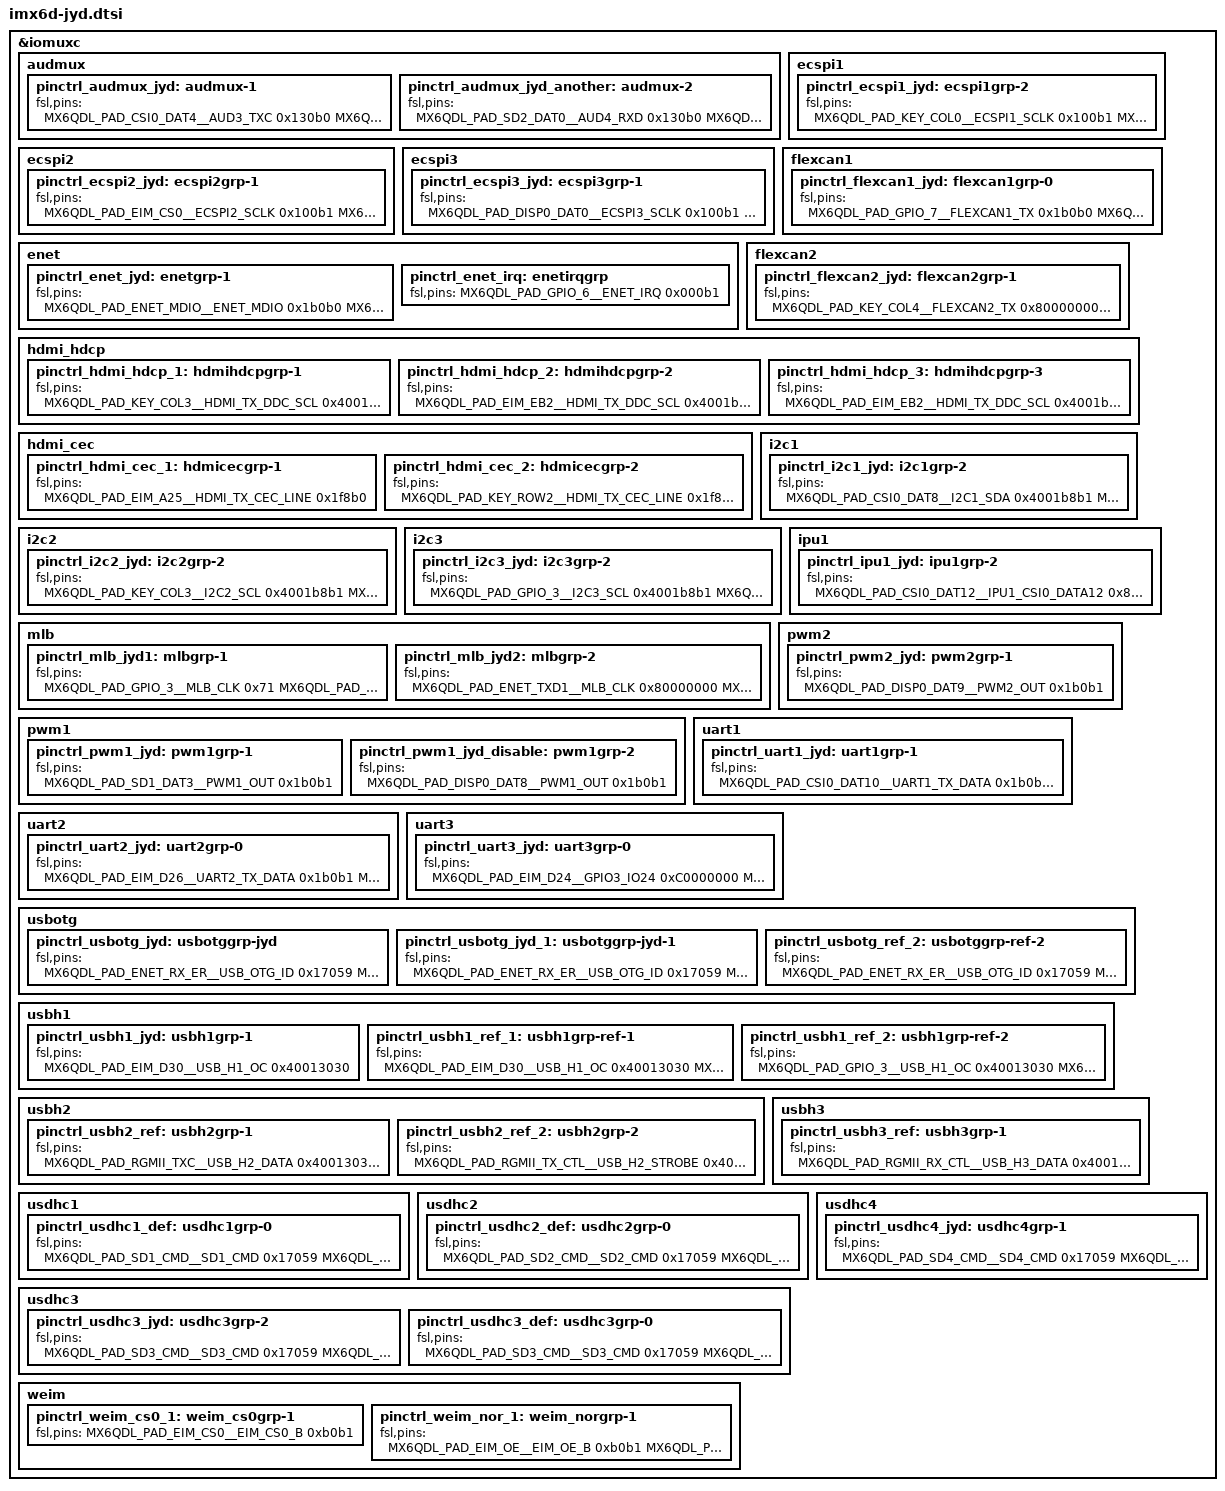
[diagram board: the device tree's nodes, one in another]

/*
 * Copyright 2013-2014 Freescale Semiconductor, Inc.
 *
 * This program is free software; you can redistribute it and/or modify
 * it under the terms of the GNU General Public License version 2 as
 * published by the Free Software Foundation.
 *
 */

#include "imx6d.dtsi"

&iomuxc {
	/* AUDMUX_PAD (AUD3/AUD4/AUD5/AUD6)*/
	audmux {
		/* EPT AUD3 (SGTL5000-Codec) */
		pinctrl_audmux_jyd: audmux-1 {
			fsl,pins = <
				MX6QDL_PAD_CSI0_DAT4__AUD3_TXC  0x130b0
				MX6QDL_PAD_CSI0_DAT5__AUD3_TXD  0x110b0
				MX6QDL_PAD_CSI0_DAT6__AUD3_TXFS 0x130b0
				MX6QDL_PAD_CSI0_DAT7__AUD3_RXD  0x130b0
			>;
		};
		/* AUD2 (Reserved) */
		pinctrl_audmux_jyd_another: audmux-2 {
			fsl,pins = <
				MX6QDL_PAD_SD2_DAT0__AUD4_RXD  0x130b0
				MX6QDL_PAD_SD2_DAT1__AUD4_TXFS 0x130b0
				MX6QDL_PAD_SD2_DAT2__AUD4_TXD  0x110b0
				MX6QDL_PAD_SD2_DAT3__AUD4_TXC  0x130b0
			>;
		};
	};

	ecspi1 {
		pinctrl_ecspi1_jyd: ecspi1grp-2 {
			fsl,pins = <
				MX6QDL_PAD_KEY_COL0__ECSPI1_SCLK 0x100b1
				MX6QDL_PAD_KEY_COL1__ECSPI1_MISO 0x100b1
				MX6QDL_PAD_KEY_ROW0__ECSPI1_MOSI 0x100b1
				MX6QDL_PAD_KEY_ROW1__ECSPI1_SS0 0x100b1
			>;
		};
	};

	ecspi2 {
		pinctrl_ecspi2_jyd: ecspi2grp-1 {
			fsl,pins = <
				MX6QDL_PAD_EIM_CS0__ECSPI2_SCLK 0x100b1
				MX6QDL_PAD_EIM_CS1__ECSPI2_MOSI 0x100b1
				MX6QDL_PAD_EIM_OE__ECSPI2_MISO 0x100b1
				MX6QDL_PAD_EIM_RW__ECSPI2_SS0 0x100b1
			>;
		};
	};
	
	ecspi3 {
		pinctrl_ecspi3_jyd: ecspi3grp-1 {
			fsl,pins = <
				MX6QDL_PAD_DISP0_DAT0__ECSPI3_SCLK 0x100b1
				MX6QDL_PAD_DISP0_DAT1__ECSPI3_MOSI 0x100b1
				MX6QDL_PAD_DISP0_DAT2__ECSPI3_MISO 0x100b1
				MX6QDL_PAD_DISP0_DAT3__ECSPI3_SS0 0x100b1
			>;
		};
	};

	enet {
		pinctrl_enet_jyd: enetgrp-1 {
			fsl,pins = <
				MX6QDL_PAD_ENET_MDIO__ENET_MDIO       0x1b0b0
				MX6QDL_PAD_ENET_MDC__ENET_MDC         0x1b0b0
				MX6QDL_PAD_RGMII_TXC__RGMII_TXC       0x1b0b0
				MX6QDL_PAD_RGMII_TD0__RGMII_TD0       0x1b0b0
				MX6QDL_PAD_RGMII_TD1__RGMII_TD1       0x1b0b0
				MX6QDL_PAD_RGMII_TD2__RGMII_TD2       0x1b0b0
				MX6QDL_PAD_RGMII_TD3__RGMII_TD3       0x1b0b0
				MX6QDL_PAD_RGMII_TX_CTL__RGMII_TX_CTL 0x1b0b0
				MX6QDL_PAD_ENET_REF_CLK__ENET_TX_CLK  0x1b0b0
				MX6QDL_PAD_RGMII_RXC__RGMII_RXC       0x1b0b0
				MX6QDL_PAD_RGMII_RD0__RGMII_RD0       0x1b0b0
				MX6QDL_PAD_RGMII_RD1__RGMII_RD1       0x1b0b0
				MX6QDL_PAD_RGMII_RD2__RGMII_RD2       0x1b0b0
				MX6QDL_PAD_RGMII_RD3__RGMII_RD3       0x1b0b0
				MX6QDL_PAD_RGMII_RX_CTL__RGMII_RX_CTL 0x1b0b0
				MX6QDL_PAD_GPIO_16__ENET_REF_CLK      0x4001b0a8
			>;
		};

		pinctrl_enet_irq: enetirqgrp {
			fsl,pins = <
				MX6QDL_PAD_GPIO_6__ENET_IRQ	      0x000b1
			>;
		};
	};
/*
	esai {
		pinctrl_esai_1: esaigrp-1 {
			fsl,pins = <
				MX6QDL_PAD_ENET_RXD0__ESAI_TX_HF_CLK 0x1b030
				MX6QDL_PAD_ENET_CRS_DV__ESAI_TX_CLK  0x1b030
				MX6QDL_PAD_ENET_RXD1__ESAI_TX_FS     0x1b030
				MX6QDL_PAD_ENET_TX_EN__ESAI_TX3_RX2  0x1b030
				MX6QDL_PAD_ENET_TXD1__ESAI_TX2_RX3   0x1b030
				MX6QDL_PAD_ENET_TXD0__ESAI_TX4_RX1   0x1b030
				MX6QDL_PAD_ENET_MDC__ESAI_TX5_RX0    0x1b030
				MX6QDL_PAD_NANDF_CS2__ESAI_TX0       0x1b030
				MX6QDL_PAD_NANDF_CS3__ESAI_TX1       0x1b030
			>;
		};

		pinctrl_esai_2: esaigrp-2 {
			fsl,pins = <
				MX6QDL_PAD_ENET_CRS_DV__ESAI_TX_CLK 0x1b030
				MX6QDL_PAD_ENET_RXD1__ESAI_TX_FS    0x1b030
				MX6QDL_PAD_ENET_TX_EN__ESAI_TX3_RX2 0x1b030
				MX6QDL_PAD_GPIO_5__ESAI_TX2_RX3     0x1b030
				MX6QDL_PAD_ENET_TXD0__ESAI_TX4_RX1  0x1b030
				MX6QDL_PAD_ENET_MDC__ESAI_TX5_RX0   0x1b030
				MX6QDL_PAD_GPIO_17__ESAI_TX0        0x1b030
				MX6QDL_PAD_NANDF_CS3__ESAI_TX1      0x1b030
				MX6QDL_PAD_ENET_MDIO__ESAI_RX_CLK   0x1b030
				MX6QDL_PAD_GPIO_9__ESAI_RX_FS       0x1b030
			>;
		};
	};
*/
	flexcan1 {
		/* EPT CAN1 */
		pinctrl_flexcan1_jyd: flexcan1grp-0 {
			fsl,pins = <
				MX6QDL_PAD_GPIO_7__FLEXCAN1_TX   0x1b0b0
				MX6QDL_PAD_GPIO_8__FLEXCAN1_RX  0x1b0b0
				MX6QDL_PAD_GPIO_19__GPIO4_IO05 0x1b0b0
			>;
		};
	};

	flexcan2 {
		/* EPT CAN2 */
		pinctrl_flexcan2_jyd: flexcan2grp-1 {
			fsl,pins = <
				MX6QDL_PAD_KEY_COL4__FLEXCAN2_TX 0x80000000
				MX6QDL_PAD_KEY_ROW4__FLEXCAN2_RX 0x80000000
			>;
		};
	};

	hdmi_hdcp {
		pinctrl_hdmi_hdcp_1: hdmihdcpgrp-1 {
			fsl,pins = <
				MX6QDL_PAD_KEY_COL3__HDMI_TX_DDC_SCL 0x4001b8b1
				MX6QDL_PAD_KEY_ROW3__HDMI_TX_DDC_SDA 0x4001b8b1
			>;
		};

		pinctrl_hdmi_hdcp_2: hdmihdcpgrp-2 {
			fsl,pins = <
				MX6QDL_PAD_EIM_EB2__HDMI_TX_DDC_SCL 0x4001b8b1
				MX6QDL_PAD_EIM_D16__HDMI_TX_DDC_SDA 0x4001b8b1
			>;
		};

		pinctrl_hdmi_hdcp_3: hdmihdcpgrp-3 {
			fsl,pins = <
				MX6QDL_PAD_EIM_EB2__HDMI_TX_DDC_SCL  0x4001b8b1
				MX6QDL_PAD_KEY_ROW3__HDMI_TX_DDC_SDA 0x4001b8b1
			>;
		};
	};

	hdmi_cec {
		pinctrl_hdmi_cec_1: hdmicecgrp-1 {
			fsl,pins = <
				MX6QDL_PAD_EIM_A25__HDMI_TX_CEC_LINE 0x1f8b0
			>;
		};

		pinctrl_hdmi_cec_2: hdmicecgrp-2 {
			fsl,pins = <
				MX6QDL_PAD_KEY_ROW2__HDMI_TX_CEC_LINE 0x1f8b0
			>;
		};
	};
	
	i2c1 {
		/* EPT I2C1 (MMA8451Q / SGTL5000 / ADV7280) */
		pinctrl_i2c1_jyd: i2c1grp-2 {
			fsl,pins = <
				MX6QDL_PAD_CSI0_DAT8__I2C1_SDA 0x4001b8b1
				MX6QDL_PAD_CSI0_DAT9__I2C1_SCL 0x4001b8b1
			>;
		};
	};

	i2c2 {
		/* EPT I2C2 (PMIC / LVDS / HDMI / TOUCH) */
		pinctrl_i2c2_jyd: i2c2grp-2 {
			fsl,pins = <
				MX6QDL_PAD_KEY_COL3__I2C2_SCL 0x4001b8b1
				MX6QDL_PAD_KEY_ROW3__I2C2_SDA 0x4001b8b1
			>;
		};
	};

	i2c3 {
		/* EPT I2C3 (ISL29032 / MAG3110 / FM-SI4754) */
		pinctrl_i2c3_jyd: i2c3grp-2 {
			fsl,pins = <
				MX6QDL_PAD_GPIO_3__I2C3_SCL 0x4001b8b1
				MX6QDL_PAD_GPIO_6__I2C3_SDA 0x4001b8b1
			>;
		};
	};

	ipu1 {
		/* EPT CSI (Camera) --  parallel port 8-bit  */
		pinctrl_ipu1_jyd: ipu1grp-2 {
			fsl,pins = <
				MX6QDL_PAD_CSI0_DAT12__IPU1_CSI0_DATA12    0x80000000
				MX6QDL_PAD_CSI0_DAT13__IPU1_CSI0_DATA13    0x80000000
				MX6QDL_PAD_CSI0_DAT14__IPU1_CSI0_DATA14    0x80000000
				MX6QDL_PAD_CSI0_DAT15__IPU1_CSI0_DATA15    0x80000000
				MX6QDL_PAD_CSI0_DAT16__IPU1_CSI0_DATA16    0x80000000
				MX6QDL_PAD_CSI0_DAT17__IPU1_CSI0_DATA17    0x80000000
				MX6QDL_PAD_CSI0_DAT18__IPU1_CSI0_DATA18    0x80000000
				MX6QDL_PAD_CSI0_DAT19__IPU1_CSI0_DATA19    0x80000000
				MX6QDL_PAD_CSI0_PIXCLK__IPU1_CSI0_PIXCLK   0x80000000
				MX6QDL_PAD_CSI0_MCLK__IPU1_CSI0_HSYNC      0x80000000
				MX6QDL_PAD_CSI0_VSYNC__IPU1_CSI0_VSYNC     0x80000000
			>;
		};
	};

	mlb {
		pinctrl_mlb_jyd1: mlbgrp-1 {
			fsl,pins = <
				MX6QDL_PAD_GPIO_3__MLB_CLK  0x71
				MX6QDL_PAD_GPIO_6__MLB_SIG  0x71
				MX6QDL_PAD_GPIO_2__MLB_DATA 0x71
			>;
		};

		pinctrl_mlb_jyd2: mlbgrp-2 {
			fsl,pins = <
				MX6QDL_PAD_ENET_TXD1__MLB_CLK 0x80000000
				MX6QDL_PAD_GPIO_6__MLB_SIG    0x80000000
				MX6QDL_PAD_GPIO_2__MLB_DATA   0x80000000
			>;
		};
	};

	pwm1 {
		/* PWM_DISP0 */
		pinctrl_pwm1_jyd: pwm1grp-1 {
			fsl,pins = <
				MX6QDL_PAD_SD1_DAT3__PWM1_OUT 0x1b0b1
			>;
		};
		
		/* PWM1 conflict with PWM_DISP0 */
		pinctrl_pwm1_jyd_disable: pwm1grp-2 {
			fsl,pins = <
				MX6QDL_PAD_DISP0_DAT8__PWM1_OUT 0x1b0b1
			>;
		};
	};
	
	pwm2 {
		/* PWM2 */
		pinctrl_pwm2_jyd: pwm2grp-1 {
			fsl,pins = <
				MX6QDL_PAD_DISP0_DAT9__PWM2_OUT 0x1b0b1
			>;
		};
	};

	uart1 {
		/* EPT DEBUG UART */
		pinctrl_uart1_jyd: uart1grp-1 {
			fsl,pins = <
				MX6QDL_PAD_CSI0_DAT10__UART1_TX_DATA 0x1b0b1
				MX6QDL_PAD_CSI0_DAT11__UART1_RX_DATA 0x1b0b1
			>;
		};
	};

	uart2 {

		/* UART2 */
		pinctrl_uart2_jyd: uart2grp-0 {
			fsl,pins = <
				MX6QDL_PAD_EIM_D26__UART2_TX_DATA 0x1b0b1
				MX6QDL_PAD_EIM_D27__UART2_RX_DATA 0x1b0b1
			>;
		};

#if 0
		/* UART2 */
		pinctrl_uart2_jyd: uart2grp-0 {
			fsl,pins = <
				MX6QDL_PAD_EIM_D26__GPIO3_IO26	0xC0000000
				MX6QDL_PAD_EIM_D27__GPIO3_IO27	0xC0000000
			>;
		};
#endif

	};

	uart3 {
#if 0
		/* UART3 */
		pinctrl_uart3_jyd: uart3grp-0 {
			fsl,pins = <
				MX6QDL_PAD_EIM_D24__UART3_TX_DATA 0x1b0b1
				MX6QDL_PAD_EIM_D25__UART3_RX_DATA 0x1b0b1
			>;
		};
#endif
		/* UART3 */

		pinctrl_uart3_jyd: uart3grp-0 {
			fsl,pins = <
				MX6QDL_PAD_EIM_D24__GPIO3_IO24	0xC0000000
				MX6QDL_PAD_EIM_D25__GPIO3_IO25	0xC0000000
			>;
		};

	};

	usbotg {
		/* EPT USB-OTG */
		pinctrl_usbotg_jyd: usbotggrp-jyd {
			fsl,pins = <
				MX6QDL_PAD_ENET_RX_ER__USB_OTG_ID 0x17059
				MX6QDL_PAD_EIM_D21__USB_OTG_OC 0x17059
			>;
		};
		pinctrl_usbotg_jyd_1: usbotggrp-jyd-1 {
			fsl,pins = <
				MX6QDL_PAD_ENET_RX_ER__USB_OTG_ID 0x17059
				MX6QDL_PAD_EIM_D21__USB_OTG_OC 0x17059
				MX6QDL_PAD_EIM_D22__USB_OTG_PWR 0x17059
			>;
		};
		
		/*pinctrl_usbotg_ref_1: usbotggrp-ref-1 {
			fsl,pins = <
				MX6QDL_PAD_GPIO_1__USB_OTG_ID 0x17059
				MX6QDL_PAD_KEY_COL4__USB_OTG_OC 0x17059
				MX6QDL_PAD_KEY_ROW4__USB_OTG_PWR 0x17059
				MX6QDL_PAD_GPIO_7__USB_OTG_HOST_MODE 0x17059
				MX6QDL_PAD_GPIO_8__USB_OTG_PWR_CTL_WAKE 0x17059
			>;
		};*/
		pinctrl_usbotg_ref_2: usbotggrp-ref-2 {
			fsl,pins = <
				MX6QDL_PAD_ENET_RX_ER__USB_OTG_ID 0x17059
				MX6QDL_PAD_EIM_D21__USB_OTG_OC 0x17059
				MX6QDL_PAD_EIM_D22__USB_OTG_PWR 0x17059
			>;
		};
	};
	
	usbh1 {
		pinctrl_usbh1_jyd: usbh1grp-1 {
			fsl,pins = <
				MX6QDL_PAD_EIM_D30__USB_H1_OC 0x40013030
			>;
		};
		pinctrl_usbh1_ref_1: usbh1grp-ref-1 {
			fsl,pins = <
				MX6QDL_PAD_EIM_D30__USB_H1_OC 0x40013030
				MX6QDL_PAD_EIM_D31__USB_H1_PWR 0x40013030
			>;
		};
		pinctrl_usbh1_ref_2: usbh1grp-ref-2 {
			fsl,pins = <
				MX6QDL_PAD_GPIO_3__USB_H1_OC 0x40013030
				MX6QDL_PAD_GPIO_0__USB_H1_PWR 0x40013030
				MX6QDL_PAD_KEY_COL2__USB_H1_PWR_CTL_WAKE 0x40013030
			>;
		};
	};
	
	usbh2 {
		pinctrl_usbh2_ref: usbh2grp-1 {
			fsl,pins = <
				MX6QDL_PAD_RGMII_TXC__USB_H2_DATA      0x40013030
				MX6QDL_PAD_RGMII_TX_CTL__USB_H2_STROBE 0x40013030
			>;
		};

		pinctrl_usbh2_ref_2: usbh2grp-2 {
			fsl,pins = <
				MX6QDL_PAD_RGMII_TX_CTL__USB_H2_STROBE 0x40017030
			>;
		};
	};
	
	usbh3 {
		pinctrl_usbh3_ref: usbh3grp-1 {
			fsl,pins = <
				MX6QDL_PAD_RGMII_RX_CTL__USB_H3_DATA    0x40013030
				MX6QDL_PAD_RGMII_RXC__USB_H3_STROBE		0x40013030
			>;
		};
	};
	
	usdhc1 {
		pinctrl_usdhc1_def: usdhc1grp-0 {
			fsl,pins = <
				MX6QDL_PAD_SD1_CMD__SD1_CMD    0x17059
				MX6QDL_PAD_SD1_CLK__SD1_CLK    0x10059
				MX6QDL_PAD_SD1_DAT0__SD1_DATA0 0x17059
				MX6QDL_PAD_SD1_DAT1__SD1_DATA1 0x17059
				MX6QDL_PAD_SD1_DAT2__SD1_DATA2 0x17059
				MX6QDL_PAD_SD1_DAT3__SD1_DATA3 0x17059
			>;
		};
	};
	
	usdhc2 {
		pinctrl_usdhc2_def: usdhc2grp-0 {
			fsl,pins = <
				MX6QDL_PAD_SD2_CMD__SD2_CMD    0x17059
				MX6QDL_PAD_SD2_CLK__SD2_CLK    0x10059
				MX6QDL_PAD_SD2_DAT0__SD2_DATA0 0x17059
				MX6QDL_PAD_SD2_DAT1__SD2_DATA1 0x17059
				MX6QDL_PAD_SD2_DAT2__SD2_DATA2 0x17059
				MX6QDL_PAD_SD2_DAT3__SD2_DATA3 0x17059
			>;
		};
	};
	
	usdhc3 {
		/* EPT SD-CARD */
		/* SD3_DAT7 	: power */
		/* NANDF_DATA00 	: detect  */
		/* NANDF_DATA01 	: write protect */
		pinctrl_usdhc3_jyd: usdhc3grp-2 {
			fsl,pins = <
				MX6QDL_PAD_SD3_CMD__SD3_CMD    0x17059
				MX6QDL_PAD_SD3_CLK__SD3_CLK    0x10059
				MX6QDL_PAD_SD3_DAT0__SD3_DATA0 0x17059
				MX6QDL_PAD_SD3_DAT1__SD3_DATA1 0x17059
				MX6QDL_PAD_SD3_DAT2__SD3_DATA2 0x17059
				MX6QDL_PAD_SD3_DAT3__SD3_DATA3 0x17059
				MX6QDL_PAD_SD3_DAT7__GPIO6_IO17 0xC0000000
				MX6QDL_PAD_NANDF_D0__GPIO2_IO00 0xC0000000
				MX6QDL_PAD_NANDF_D1__GPIO2_IO01 0xC0000000
			>;
		};
		
		pinctrl_usdhc3_def: usdhc3grp-0 {
			fsl,pins = <
				MX6QDL_PAD_SD3_CMD__SD3_CMD    0x17059
				MX6QDL_PAD_SD3_CLK__SD3_CLK    0x10059
				MX6QDL_PAD_SD3_DAT0__SD3_DATA0 0x17059
				MX6QDL_PAD_SD3_DAT1__SD3_DATA1 0x17059
				MX6QDL_PAD_SD3_DAT2__SD3_DATA2 0x17059
				MX6QDL_PAD_SD3_DAT3__SD3_DATA3 0x17059
				MX6QDL_PAD_SD3_DAT4__SD3_DATA4 0x17059
				MX6QDL_PAD_SD3_DAT5__SD3_DATA5 0x17059
				MX6QDL_PAD_SD3_DAT6__SD3_DATA6 0x17059
				MX6QDL_PAD_SD3_DAT7__SD3_DATA7 0x17059
			>;
		};
	};

	usdhc4 {
		/* EPT EMMC */
		pinctrl_usdhc4_jyd: usdhc4grp-1 {
			fsl,pins = <
				MX6QDL_PAD_SD4_CMD__SD4_CMD    0x17059
				MX6QDL_PAD_SD4_CLK__SD4_CLK    0x10059
				MX6QDL_PAD_SD4_DAT0__SD4_DATA0 0x17059
				MX6QDL_PAD_SD4_DAT1__SD4_DATA1 0x17059
				MX6QDL_PAD_SD4_DAT2__SD4_DATA2 0x17059
				MX6QDL_PAD_SD4_DAT3__SD4_DATA3 0x17059
				MX6QDL_PAD_SD4_DAT4__SD4_DATA4 0x17059
				MX6QDL_PAD_SD4_DAT5__SD4_DATA5 0x17059
				MX6QDL_PAD_SD4_DAT6__SD4_DATA6 0x17059
				MX6QDL_PAD_SD4_DAT7__SD4_DATA7 0x17059
			>;
		};
	};

	weim {
		pinctrl_weim_cs0_1: weim_cs0grp-1 {
			fsl,pins = <
				MX6QDL_PAD_EIM_CS0__EIM_CS0_B   0xb0b1
			>;
		};

		pinctrl_weim_nor_1: weim_norgrp-1 {
			fsl,pins = <
				MX6QDL_PAD_EIM_OE__EIM_OE_B     0xb0b1
				MX6QDL_PAD_EIM_RW__EIM_RW       0xb0b1
				MX6QDL_PAD_EIM_WAIT__EIM_WAIT_B 0xb060
				
				MX6QDL_PAD_EIM_D16__EIM_DATA16 0x1b0b0
				MX6QDL_PAD_EIM_D17__EIM_DATA17 0x1b0b0
				MX6QDL_PAD_EIM_D18__EIM_DATA18 0x1b0b0
				MX6QDL_PAD_EIM_D19__EIM_DATA19 0x1b0b0
				MX6QDL_PAD_EIM_D20__EIM_DATA20 0x1b0b0
				MX6QDL_PAD_EIM_D21__EIM_DATA21 0x1b0b0
				MX6QDL_PAD_EIM_D22__EIM_DATA22 0x1b0b0
				MX6QDL_PAD_EIM_D23__EIM_DATA23 0x1b0b0
				MX6QDL_PAD_EIM_D24__EIM_DATA24 0x1b0b0
				MX6QDL_PAD_EIM_D25__EIM_DATA25 0x1b0b0
				MX6QDL_PAD_EIM_D26__EIM_DATA26 0x1b0b0
				MX6QDL_PAD_EIM_D27__EIM_DATA27 0x1b0b0
				MX6QDL_PAD_EIM_D28__EIM_DATA28 0x1b0b0
				MX6QDL_PAD_EIM_D29__EIM_DATA29 0x1b0b0
				MX6QDL_PAD_EIM_D30__EIM_DATA30 0x1b0b0
				MX6QDL_PAD_EIM_D31__EIM_DATA31 0x1b0b0
				
				MX6QDL_PAD_EIM_A23__EIM_ADDR23 0xb0b1
				MX6QDL_PAD_EIM_A22__EIM_ADDR22 0xb0b1
				MX6QDL_PAD_EIM_A21__EIM_ADDR21 0xb0b1
				MX6QDL_PAD_EIM_A20__EIM_ADDR20 0xb0b1
				MX6QDL_PAD_EIM_A19__EIM_ADDR19 0xb0b1
				MX6QDL_PAD_EIM_A18__EIM_ADDR18 0xb0b1
				MX6QDL_PAD_EIM_A17__EIM_ADDR17 0xb0b1
				MX6QDL_PAD_EIM_A16__EIM_ADDR16 0xb0b1
				MX6QDL_PAD_EIM_DA15__EIM_AD15  0xb0b1
				MX6QDL_PAD_EIM_DA14__EIM_AD14  0xb0b1
				MX6QDL_PAD_EIM_DA13__EIM_AD13  0xb0b1
				MX6QDL_PAD_EIM_DA12__EIM_AD12  0xb0b1
				MX6QDL_PAD_EIM_DA11__EIM_AD11  0xb0b1
				MX6QDL_PAD_EIM_DA10__EIM_AD10  0xb0b1
				MX6QDL_PAD_EIM_DA9__EIM_AD09   0xb0b1
				MX6QDL_PAD_EIM_DA8__EIM_AD08   0xb0b1
				MX6QDL_PAD_EIM_DA7__EIM_AD07   0xb0b1
				MX6QDL_PAD_EIM_DA6__EIM_AD06   0xb0b1
				MX6QDL_PAD_EIM_DA5__EIM_AD05   0xb0b1
				MX6QDL_PAD_EIM_DA4__EIM_AD04   0xb0b1
				MX6QDL_PAD_EIM_DA3__EIM_AD03   0xb0b1
				MX6QDL_PAD_EIM_DA2__EIM_AD02   0xb0b1
				MX6QDL_PAD_EIM_DA1__EIM_AD01   0xb0b1
				MX6QDL_PAD_EIM_DA0__EIM_AD00   0xb0b1
			>;
		};
	};
	
};

